AUTOSAR XML (schema 00051)
package /Components
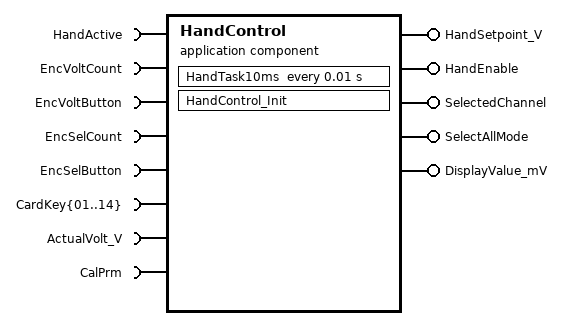
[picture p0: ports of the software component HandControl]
  application sw component type HandControl
    20 x require port:
      HandActive: nonqueued-receiver-com-spec{data-element=HandActive, init-value=0}, required-interface=HandActive
      EncVoltCount: nonqueued-receiver-com-spec{data-element=EncVoltCount, init-value=0}, required-interface=EncVoltCount
      EncVoltButton: nonqueued-receiver-com-spec{data-element=EncVoltButton, init-value=0}, required-interface=EncVoltButton
      EncSelCount: nonqueued-receiver-com-spec{data-element=EncSelCount, init-value=0}, required-interface=EncSelCount
      EncSelButton: nonqueued-receiver-com-spec{data-element=EncSelButton, init-value=0}, required-interface=EncSelButton
      CardKey{01..14}: nonqueued-receiver-com-spec{data-element=CardKey{01..14}, init-value=0}, required-interface=CardKey{01..14}
      ActualVolt_V: nonqueued-receiver-com-spec{data-element=ActualVolt_V, init-value=14 x 0}, required-interface=ActualVolt_V
    5 x provide port:
      HandSetpoint_V: nonqueued-sender-com-spec{data-element=HandSetpoint_V, init-value=14 x 0}, provided-interface=HandSetpoint_V
      HandEnable: nonqueued-sender-com-spec{data-element=HandEnable, init-value=14 x 0}, provided-interface=HandEnable
      SelectedChannel: nonqueued-sender-com-spec{data-element=SelectedChannel, init-value=0}, provided-interface=SelectedChannel
      SelectAllMode: nonqueued-sender-com-spec{data-element=SelectAllMode, init-value=0}, provided-interface=SelectAllMode
      DisplayValue_mV: nonqueued-sender-com-spec{data-element=DisplayValue_mV, init-value=0}, provided-interface=DisplayValue_mV
    require port CalPrm: required-interface=CalPrm
      required-com-specs:
        init-value=CalPrm_CoarseStep_mV:15, parameter=CoarseStep_mV
        init-value=CalPrm_FineStep_mV:1, parameter=FineStep_mV
        init-value=CalPrm_HandMinSetpoint_V:0.7, parameter=HandMinSetpoint_V
        init-value=CalPrm_SetpointLimit_V:5, parameter=SetpointLimit_V
        init-value=CalPrm_DisplayFilter_cycles:30, parameter=DisplayFilter_cycles
        init-value=CalPrm_DisplayHyst_mV:3, parameter=DisplayHyst_mV
        init-value=CalPrm_DisplayJump_mV:20, parameter=DisplayJump_mV
        init-value=CalPrm_CountsPerStep:4, parameter=CountsPerStep
        init-value=CalPrm_KeyDebounce_cycles:3, parameter=KeyDebounce_cycles
    behavior HandControl_IB: handle-termination-and-restart=NO-SUPPORT
      timing event Event_HandTask10ms: start-on-event=HandTask10ms, period=0.01
      runnable HandControl_Init
      runnable HandTask10ms
        data-receive-point-by-arguments:
          20 x access:
            IN_ActualVolt_V_ActualVolt_V: accessed-variable=ActualVolt_V.ActualVolt_V
            IN_CardKey{01..14}_CardKey{01..14}: accessed-variable=CardKey{01..14}.CardKey{01..14}
            IN_EncSelButton_EncSelButton: accessed-variable=EncSelButton.EncSelButton
            IN_EncSelCount_EncSelCount: accessed-variable=EncSelCount.EncSelCount
            IN_EncVoltButton_EncVoltButton: accessed-variable=EncVoltButton.EncVoltButton
            IN_EncVoltCount_EncVoltCount: accessed-variable=EncVoltCount.EncVoltCount
            IN_HandActive_HandActive: accessed-variable=HandActive.HandActive
        data-send-points:
          5 x access:
            OUT_HandSetpoint_V_HandSetpoint_V: accessed-variable=HandSetpoint_V.HandSetpoint_V
            OUT_HandEnable_HandEnable: accessed-variable=HandEnable.HandEnable
            OUT_SelectedChannel_SelectedChannel: accessed-variable=SelectedChannel.SelectedChannel
            OUT_SelectAllMode_SelectAllMode: accessed-variable=SelectAllMode.SelectAllMode
            OUT_DisplayValue_mV_DisplayValue_mV: accessed-variable=DisplayValue_mV.DisplayValue_mV
        9 x parameter access:
          CALPRM_CalPrm_CoarseStep_mV: accessed-parameter=CalPrm.CoarseStep_mV
          CALPRM_CalPrm_CountsPerStep: accessed-parameter=CalPrm.CountsPerStep
          CALPRM_CalPrm_DisplayFilter_cycles: accessed-parameter=CalPrm.DisplayFilter_cycles
          CALPRM_CalPrm_DisplayHyst_mV: accessed-parameter=CalPrm.DisplayHyst_mV
          CALPRM_CalPrm_DisplayJump_mV: accessed-parameter=CalPrm.DisplayJump_mV
          CALPRM_CalPrm_FineStep_mV: accessed-parameter=CalPrm.FineStep_mV
          CALPRM_CalPrm_HandMinSetpoint_V: accessed-parameter=CalPrm.HandMinSetpoint_V
          CALPRM_CalPrm_KeyDebounce_cycles: accessed-parameter=CalPrm.KeyDebounce_cycles
          CALPRM_CalPrm_SetpointLimit_V: accessed-parameter=CalPrm.SetpointLimit_V
      variation point proxy CellCount: category=VALUE, value-access=integer-value-variation-point=CellCount
